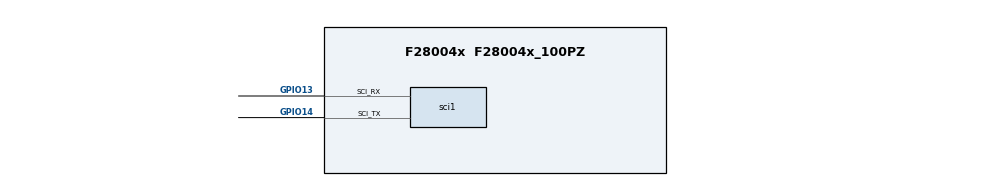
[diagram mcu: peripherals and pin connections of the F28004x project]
/**
 * @cliArgs --device "F28004x" --part "F28004x_100PZ" --package "F28004x_100PZ" --context "system" --product "C2000WARE@5.01.00.00"
 * @versions {"tool":"1.21.0+3721"}
 */

/**
 * Import the modules used in this configuration.
 */
const cputimer  = scripting.addModule("/driverlib/cputimer.js", {}, false);
const cputimer1 = cputimer.addInstance();
const sci       = scripting.addModule("/driverlib/sci.js", {}, false);
const sci1      = sci.addInstance();

/**
 * Write custom configuration values to the imported modules.
 */
cputimer1.$name          = "SWTIRMER";
cputimer1.timerPrescaler = 2;
cputimer1.timerPeriod    = 33333333;
cputimer1.startTimer     = true;

sci1.parity                = "SCI_CONFIG_PAR_EVEN";
sci1.$name                 = "DEBUG_SCI";
sci1.sci.sci_rxPin.$assign = "GPIO13";
sci1.sci.sci_txPin.$assign = "GPIO14";

/**
 * Pinmux solution for unlocked pins/peripherals. This ensures that minor changes to the automatic solver in a future
 * version of the tool will not impact the pinmux you originally saw.  These lines can be completely deleted in order to
 * re-solve from scratch.
 */
sci1.sci.$suggestSolution = "SCIB";
